# ioSTC8A8K16S2A12 register map
Registers are 8-bit, access not given, no defined reset value unless marked. A register's access mark holds for its fields unless they carry their own. Addresses are absolute; registers are grouped by the start of their names; [hi:lo] are bit positions; {n}, {i} and the like mark numbered series.

## SFR
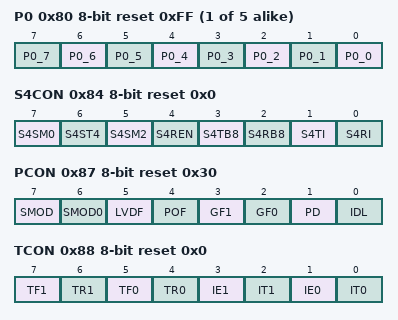
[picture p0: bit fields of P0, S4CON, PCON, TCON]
{0x80+0x10*i} P{i} reset 0xFF (i=0..4) — Port {i}
  [n] P{i}_{n} (n=0..7)
0x82 DPL reset 0x0 — Data Pointer 0 Low
0x83 DPH reset 0x0 — Data Pointer 0 High
0x84 S4CON reset 0x0 — Serial 4 Control
  [7] S4SM0, [6] S4ST4, [5] S4SM2, [4] S4REN, [3] S4TB8, [2] S4RB8, [1] S4TI, [0] S4RI
0x85 S4BUF reset 0x0 — Serial 4 Data Buffer
0x87 PCON reset 0x30 — Power Control
  [7] SMOD, [6] SMOD0, [5] LVDF, [4] POF, [3] GF1, [2] GF0, [1] PD, [0] IDL
0x88 TCON reset 0x0 — Timer Control
  [7] TF1, [6] TR1, [5] TF0, [4] TR0, [3] IE1, [2] IT1, [1] IE0, [0] IT0
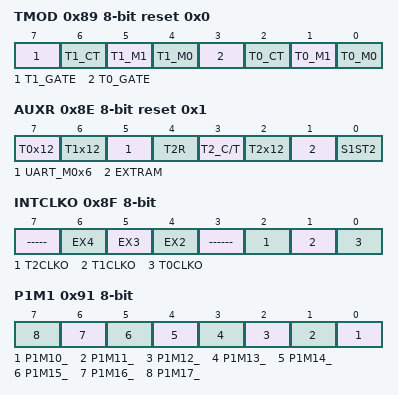
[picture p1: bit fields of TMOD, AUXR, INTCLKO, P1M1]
0x89 TMOD reset 0x0 — Timer 0 and 1 mode
  [7] T1_GATE, [6] T1_CT, [5] T1_M1, [4] T1_M0, [3] T0_GATE, [2] T0_CT, [1] T0_M1, [0] T0_M0
0x8A TL0 reset 0x0 — Timer0 Low
0x8B TL1 reset 0x0 — Timer1 Low
0x8C TH0 reset 0x0 — Timer0 High
0x8D TH1 reset 0x0 — Timer1 High
0x8E AUXR reset 0x1 — Auxiliary register
  [7] T0x12, [6] T1x12, [5] UART_M0x6, [4] T2R, [3] T2_C/T, [2] T2x12, [1] EXTRAM, [0] S1ST2
0x8F INTCLKO — interrupt and Timer output control
  [7] -----, [6] EX4, [5] EX3, [4] EX2, [3] ------, [2] T2CLKO, [1] T1CLKO, [0] T0CLKO
0x91 P1M1 — Port 1 output mode 1
  [n-10] P1M{n}_ (n=10..17)
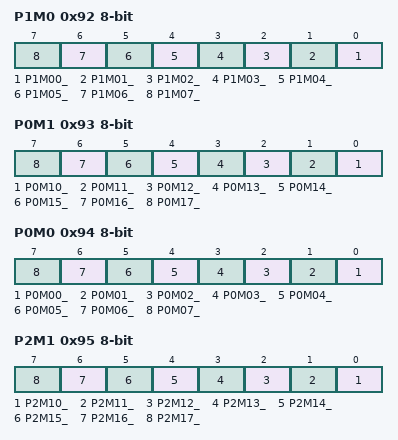
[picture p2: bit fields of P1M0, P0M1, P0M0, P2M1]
0x92 P1M0 — Port 1 output mode 0
  [n] P1M{n:02}_ (n=0..7)
0x93 P0M1 — Port 0 output mode 1
  [n-10] P0M{n}_ (n=10..17)
0x94 P0M0 — Port 0 output mode 0
  [n] P0M{n:02}_ (n=0..7)
0x95 P2M1 — Port 2 output mode 1
  [n-10] P2M{n}_ (n=10..17)
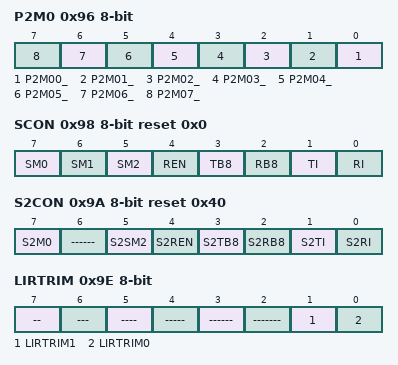
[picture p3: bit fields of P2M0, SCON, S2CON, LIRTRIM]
0x96 P2M0 — Port 2 output mode 0
  [n] P2M{n:02}_ (n=0..7)
0x98 SCON reset 0x0 — Serial 1 Control
  [7] SM0, [6] SM1, [5] SM2, [4] REN, [3] TB8, [2] RB8, [1] TI, [0] RI
0x99 SBUF reset 0x0 — Serial 1 Data Buffer
0x9A S2CON reset 0x40 — Serial 2 Control
  [7] S2M0, [6] ------, [5] S2SM2, [4] S2REN, [3] S2TB8, [2] S2RB8, [1] S2TI, [0] S2RI
0x9B S2BUF — Serial 2 Data Buffer
0x9E LIRTRIM — IRC frequency coarse tuning register
  [7] --, [6] ---, [5] ----, [4] -----, [3] ------, [2] -------, [1] LIRTRIM1, [0] LIRTRIM0
0x9F IRTRIM — IRC frequency fine tuning register
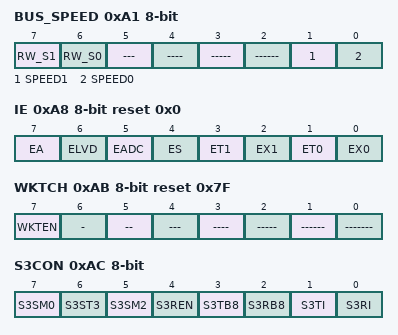
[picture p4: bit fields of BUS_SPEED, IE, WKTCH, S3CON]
0xA1 BUS_SPEED — Bus speed Control register
  [7] RW_S1, [6] RW_S0, [5] ---, [4] ----, [3] -----, [2] ------, [1] SPEED1, [0] SPEED0
0xA8 IE reset 0x0 — interrupt enable resister
  [7] EA, [6] ELVD, [5] EADC, [4] ES, [3] ET1, [2] EX1, [1] ET0, [0] EX0
0xA9 SADDR — Serial 1 Slave Addr
0xAA WKTCL reset 0xFF — Wake up Timer Low
0xAB WKTCH reset 0x7F — Wake up Timer High
  [7] WKTEN, [6] -, [5] --, [4] ---, [3] ----, [2] -----, [1] ------, [0] -------
0xAC S3CON — Serial 3 Control
  [7] S3SM0, [6] S3ST3, [5] S3SM2, [4] S3REN, [3] S3TB8, [2] S3RB8, [1] S3TI, [0] S3RI
0xAD S3BUF — Serial3 Data Buffer
0xAE TA — Data Pointer sequence control
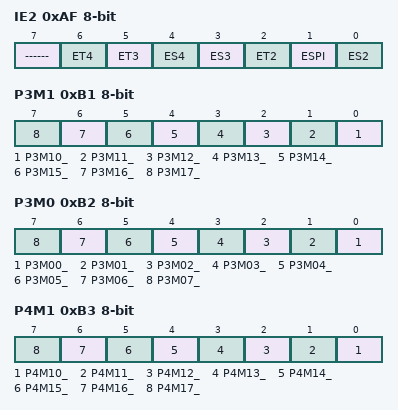
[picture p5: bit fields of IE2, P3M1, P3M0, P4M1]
0xAF IE2 — interrupt enable resister2
  [7] ------, [6] ET4, [5] ET3, [4] ES4, [3] ES3, [2] ET2, [1] ESPI, [0] ES2
0xB1 P3M1 — Port 3 output mode 1
  [n-10] P3M{n}_ (n=10..17)
0xB2 P3M0 — Port 3 output mode 0
  [n] P3M{n:02}_ (n=0..7)
0xB3 P4M1 — Port 4 output mode 1
  [n-10] P4M{n}_ (n=10..17)
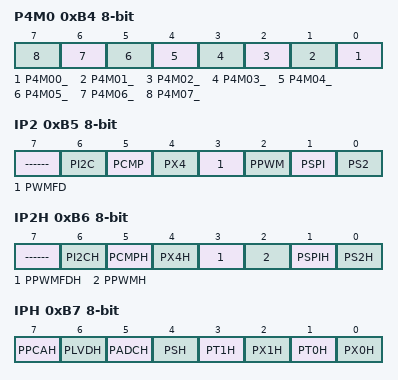
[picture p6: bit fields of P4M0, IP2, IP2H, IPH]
0xB4 P4M0 — Port 4 output mode 0
  [n] P4M{n:02}_ (n=0..7)
0xB5 IP2 — interrupt priority resister2
  [7] ------, [6] PI2C, [5] PCMP, [4] PX4, [3] PWMFD, [2] PPWM, [1] PSPI, [0] PS2
0xB6 IP2H — interrupt priority high resister2
  [7] ------, [6] PI2CH, [5] PCMPH, [4] PX4H, [3] PPWMFDH, [2] PPWMH, [1] PSPIH, [0] PS2H
0xB7 IPH — interrupt priority high resister
  [7] PPCAH, [6] PLVDH, [5] PADCH, [4] PSH, [3] PT1H, [2] PX1H, [1] PT0H, [0] PX0H
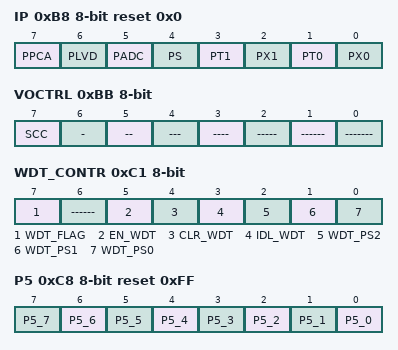
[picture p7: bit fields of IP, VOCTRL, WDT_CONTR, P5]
0xB8 IP reset 0x0 — interrupt priority resister1
  [7] PPCA, [6] PLVD, [5] PADC, [4] PS, [3] PT1, [2] PX1, [1] PT0, [0] PX0
0xB9 SADEN — Serial 1 Slave Addr Shield
0xBB VOCTRL — Voltage control register
  [7] SCC, [6] -, [5] --, [4] ---, [3] ----, [2] -----, [1] ------, [0] -------
0xC1 WDT_CONTR — Watchdog control register
  [7] WDT_FLAG, [6] ------, [5] EN_WDT, [4] CLR_WDT, [3] IDL_WDT, [2] WDT_PS2, [1] WDT_PS1, [0] WDT_PS0
0xC8 P5 reset 0xFF — Port 5
  [n] P5_{n} (n=0..7)
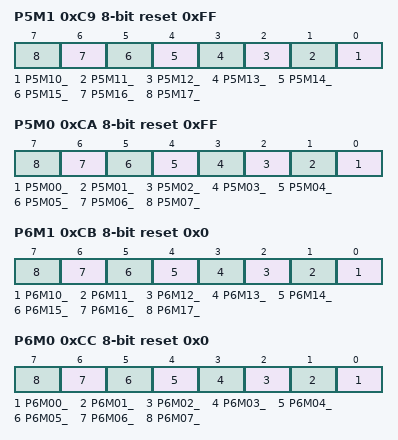
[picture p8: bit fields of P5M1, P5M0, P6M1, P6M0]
0xC9 P5M1 reset 0xFF — Port 5 output mode 1
  [n-10] P5M{n}_ (n=10..17)
0xCA P5M0 reset 0xFF — Port 5 output mode 0
  [n] P5M{n:02}_ (n=0..7)
0xCB P6M1 reset 0x0 — Port 6 output mode 1
  [n-10] P6M{n}_ (n=10..17)
0xCC P6M0 reset 0x0 — Port 6 output mode 0
  [n] P6M{n:02}_ (n=0..7)
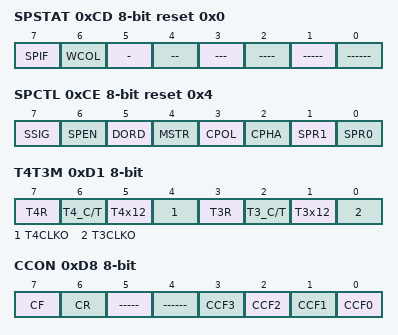
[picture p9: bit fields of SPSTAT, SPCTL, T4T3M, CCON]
0xCD SPSTAT reset 0x0 — SPI status register
  [7] SPIF, [6] WCOL, [5] -, [4] --, [3] ---, [2] ----, [1] -----, [0] ------
0xCE SPCTL reset 0x4 — SPI control register
  [7] SSIG, [6] SPEN, [5] DORD, [4] MSTR, [3] CPOL, [2] CPHA, [1] SPR1, [0] SPR0
0xCF SPDAT reset 0x0 — SPI data register
0xD1 T4T3M — Timer4/3 Control
  [7] T4R, [6] T4_C/T, [5] T4x12, [4] T4CLKO, [3] T3R, [2] T3_C/T, [1] T3x12, [0] T3CLKO
0xD2 T4H — Timer4 High
0xD3 T4L — Timer4 Low
0xD4 T3H — Timer3 High
0xD5 T3L — Timer3 Low
0xD6 T2H — Timer2 High
0xD7 T2L — Timer2 Low
0xD8 CCON — PCA control register
  [7] CF, [6] CR, [5] -----, [4] ------, [n] CCF{n} (n=0..3)
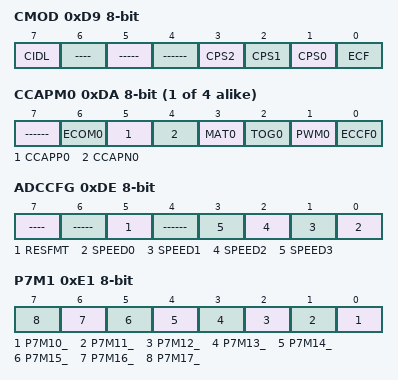
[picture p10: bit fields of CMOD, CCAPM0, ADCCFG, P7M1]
0xD9 CMOD — PCA mode register
  [7] CIDL, [6] ----, [5] -----, [4] ------, [3] CPS2, [2] CPS1, [1] CPS0, [0] ECF
{0xDA+i} CCAPM{i} (i=0..3) — PCA Module{i} control register
  [7] ------, [6] ECOM{i}, [5] CCAPP{i}, [4] CCAPN{i}, [3] MAT{i}, [2] TOG{i}, [1] PWM{i}, [0] ECCF{i}
0xDE ADCCFG — A/D config register
  [7] ----, [6] -----, [5] RESFMT, [4] ------, [n] SPEED{n} (n=0..3)
0xE1 P7M1 — Port 7 output mode 1
  [n-10] P7M{n}_ (n=10..17)
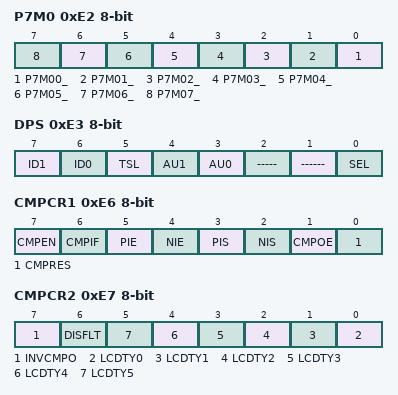
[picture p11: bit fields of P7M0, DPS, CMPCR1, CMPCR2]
0xE2 P7M0 — Port 7 output mode 0
  [n] P7M{n:02}_ (n=0..7)
0xE3 DPS — Data Pointer Select
  [7] ID1, [6] ID0, [5] TSL, [4] AU1, [3] AU0, [2] -----, [1] ------, [0] SEL
0xE6 CMPCR1 — Comparator control register1
  [7] CMPEN, [6] CMPIF, [5] PIE, [4] NIE, [3] PIS, [2] NIS, [1] CMPOE, [0] CMPRES
0xE7 CMPCR2 — Comparator control register2
  [7] INVCMPO, [6] DISFLT, [n] LCDTY{n} (n=0..5)
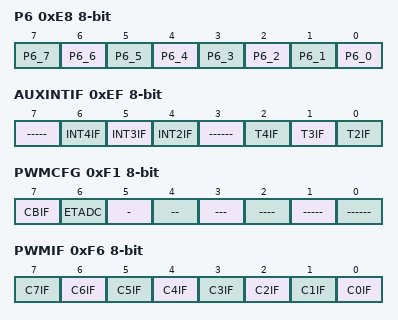
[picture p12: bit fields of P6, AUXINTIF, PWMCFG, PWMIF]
0xE8 P6 — Port 6
  [n] P6_{n} (n=0..7)
0xE9 CL — PCA Counter Low
{0xEA+i} CCAP{i}L (i=0..3) — PCA Module{i} Low
0xEF AUXINTIF — extern interrupt flag
  [7] -----, [6] INT4IF, [5] INT3IF, [4] INT2IF, [3] ------, [2] T4IF, [1] T3IF, [0] T2IF
0xF1 PWMCFG — Enhanced PWM config register
  [7] CBIF, [6] ETADC, [5] -, [4] --, [3] ---, [2] ----, [1] -----, [0] ------
0xF6 PWMIF — Enhanced PWM interrupt
  [n] C{n}IF (n=0..7)
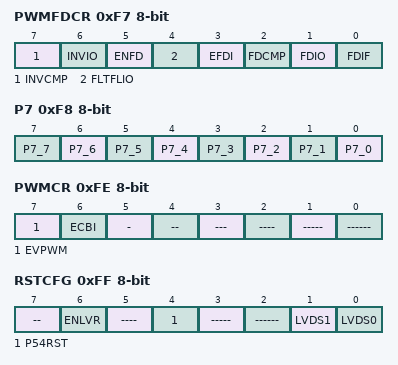
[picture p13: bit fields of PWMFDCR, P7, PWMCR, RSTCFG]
0xF7 PWMFDCR — PWM Anomaly detection control
  [7] INVCMP, [6] INVIO, [5] ENFD, [4] FLTFLIO, [3] EFDI, [2] FDCMP, [1] FDIO, [0] FDIF
0xF8 P7 — Port 7
  [n] P7_{n} (n=0..7)
0xF9 CH — PCA Counter High
{0xFA+i} CCAP{i}H (i=0..3) — PCA Module{i} High
0xFE PWMCR — PWM control register
  [7] EVPWM, [6] ECBI, [5] -, [4] --, [3] ---, [2] ----, [1] -----, [0] ------
0xFF RSTCFG — Voltage control register
  [7] --, [6] ENLVR, [5] ----, [4] P54RST, [3] -----, [2] ------, [1] LVDS1, [0] LVDS0

## P
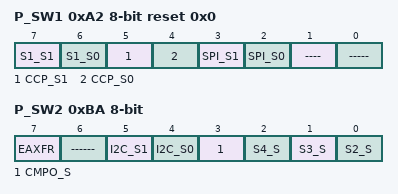
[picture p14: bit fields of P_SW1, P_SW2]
0xA2 P_SW1 reset 0x0 — Peripheral port switch register1
  [7] S1_S1, [6] S1_S0, [5] CCP_S1, [4] CCP_S0, [3] SPI_S1, [2] SPI_S0, [1] ----, [0] -----
0xBA P_SW2 — Peripheral port switch register2
  [7] EAXFR, [6] ------, [5] I2C_S1, [4] I2C_S0, [3] CMPO_S, [2] S4_S, [1] S3_S, [0] S2_S

## ADC
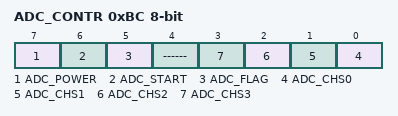
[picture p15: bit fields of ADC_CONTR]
0xBC ADC_CONTR — A/D control register
  [7] ADC_POWER, [6] ADC_START, [5] ADC_FLAG, [4] ------, [n] ADC_CHS{n} (n=0..3)
0xBD ADC_RES — A/D result high
0xBE ADC_RESL — A/D result low

## IAP
0xC2 IAP_DATA reset 0xFF
0xC3 IAP_ADDRH — IAP addr high
0xC4 IAP_ADDRL — IAP addr low
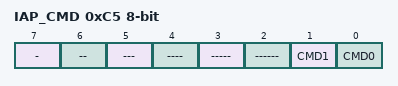
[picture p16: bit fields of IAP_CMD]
0xC5 IAP_CMD — IAP command
  [7] -, [6] --, [5] ---, [4] ----, [3] -----, [2] ------, [1] CMD1, [0] CMD0
0xC6 IAP_TRIG — IAP trigger
0xC7 IAP_CONTR — IAP control
  [7] IAPEN, [6] SWBS, [5] SWRST, [4] CMD_FAIL, [3] ------, [2] IAP_WT2, [1] IAP_WT1, [0] IAP_WT0

## PCA
{0xF2+i} PCA_PWM{i} (i=0..3) — PCA{i} PWM mode register
  [7] EBS{10i+1:02}, [6] EBS{10i:02}, [5] XXCAP{i}H1, [4] XXCAP{i}H0, [3] XXCAP{i}L1, [2] XXCAP{i}L0, [1] EPC{i}H, [0] EPC{i}L

## Device_Code
{0xFE6+i} Device_ID{i} (i=0..6) — ROM ID{i}

## Bandgap_Code
0xFE4 Bandgap_H — Bandgap
0xFE5 Bandgap_L — Bandgap

## WakeUp_Code
0xFE2 WakeUp_Fre_H — 32K_PowerDown_Fre
0xFE3 WakeUp_Fre_L — 32K_PowerDown_Fre

## SFR_Code
0xFE0 24MHz_IRC
0xFE1 22184kHz_IRC — 22.184MHz_IRC
